# MCBSP register map
Vendor: Texas Instruments
Peripheral module from a debugger description file (folder 66AK2G0x_66AK2G1x).
Registers are 32-bit, read-write, reset values left out (the file's numbers can be read two ways) unless marked. A register's access mark holds for its fields unless they carry their own. Offsets are as the file gives them; lines under a group give offsets from that group; [hi:lo] are bit positions; {n}, {i} and the like mark numbered series; 'fields as' and 'values as' point back to an identical list; <NAME> marks a mode.

## MCBSP
0x00 MCBSP_DRR ro
  [31:0] DR — Data receive register value to be written to the data bus. Value is 0-FFFF FFFFh
0x04 MCBSP_DXR
  [31:0] DX — Data transmit register value to be loaded into the data transmit shift register (XSR).Value is 0-FFFF FFFFh.
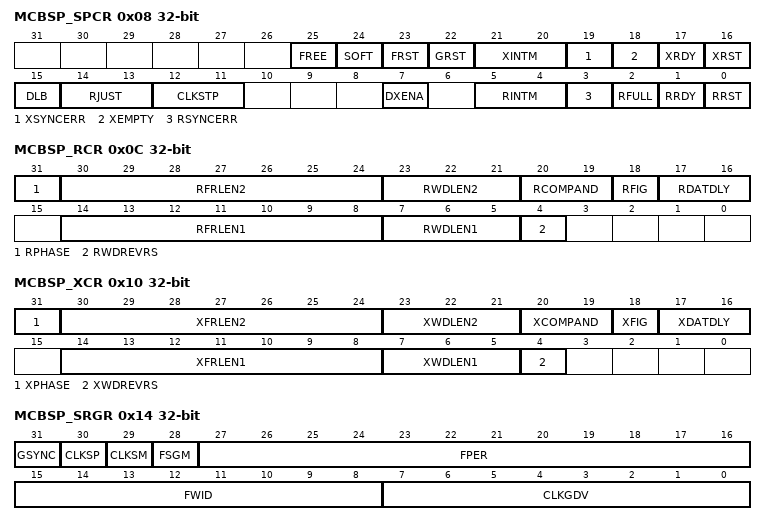
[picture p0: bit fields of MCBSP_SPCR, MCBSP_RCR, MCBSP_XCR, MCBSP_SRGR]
0x08 MCBSP_SPCR access per field
  [25] FREE rw — Free-running enable mode bit. This bit is used in conjunction with SOFT bit to determine state of serial port clock during emulation halt.
  [24] SOFT rw — Soft bit enable mode bit. This bit is used in conjunction with FREE bit to determine state of serial port clock during emulation halt. This bit has no effect if FREE = 1.
  [23] FRST rw — Frame-sync generator reset bit.
  [22] GRST rw — Sample-rate generator reset bit.
  [21:20] XINTM rw — Transmit interrupt (XINT) mode bit.
  [19] XSYNCERR rw — Transmit synchronization error bit. Writing a 1 to XSYNCERR sets the error condition when the transmitter is enabled (XRST = 1). Thus, it is used mainly for testing purposes or if this operation is desired.
  [18] XEMPTY ro — Transmit shift register empty bit.
  [17] XRDY ro — Transmitter ready bit.
  [16] XRST rw — Transmitter reset bit resets or enables the transmitter.
  [15] DLB rw — Digital loop back mode enable bit.
  [14:13] RJUST rw — Receive sign-extension and justification mode bit.
  [12:11] CLKSTP ro — Clock stop mode bit.
  [7] DXENA rw — DX enabler bit. See for details on the DX enabler bit.
  [5:4] RINTM rw — Receive interrupt (RINT) mode bit.
  [3] RSYNCERR rw — Receive synchronization error bit. Writing a 1 to RSYNCERR sets the error condition when the receiver is enabled (RRST = 1). Thus, it is used mainly for testing purposes or if this operation is desired.
  [2] RFULL ro — Receive shift register full bit.
  [1] RRDY ro — Receiver ready bit.
  [0] RRST rw — Receiver reset bit resets or enables the receiver.
0x0C MCBSP_RCR access per field
  [31] RPHASE rw — Receive phases bit.
  [30:24] RFRLEN2 rw — Specifies the receive frame length (number of words) in phase 2.
  [23:21] RWDLEN2 rw — Specifies the receive word length (number of bits) in phase 2.
  [20:19] RCOMPAND rw — Receive companding mode bit. Modes other than 00 are only enabled when RWDLEN1/2 bit is 000 (indicating 8-bit data).
  [18] RFIG rw — Receive frame ignore bit.
  [17:16] RDATDLY rw — Receive data delay bit.
  [14:8] RFRLEN1 rw — Specifies the receive frame length (number of words) in phase 1.
  [7:5] RWDLEN1 rw — Specifies the receive word length (number of bits) in phase 1.
  [4] RWDREVRS rw — Receive 32-bit reversal enable bit.
0x10 MCBSP_XCR access per field
  [31] XPHASE rw — Transmit phases bit.
  [30:24] XFRLEN2 rw — Specifies the transmit frame length (number of words) in phase 2.
  [23:21] XWDLEN2 rw — Specifies the transmit word length (number of bits) in phase 2.
  [20:19] XCOMPAND rw — Transmit companding mode bit. Modes other than 00 are only enabled when XWDLEN1/2 bit is 000 (indicating 8-bit data).
  [18] XFIG rw — Transmit frame ignore bit.
  [17:16] XDATDLY rw — Transmit data delay bit.
  [14:8] XFRLEN1 rw — Specifies the transmit frame length (number of words) in phase 1.
  [7:5] XWDLEN1 rw — Specifies the transmit word length (number of bits) in phase 1.
  [4] XWDREVRS rw — Transmit 32-bit reversal feature enable bit.
0x14 MCBSP_SRGR
  [31] GSYNC — Sample-rate generator clock synchronization bit is only used when CLKS drives the sample-rate generator clock (CLKSM = 0).
  [30] CLKSP — CLKS polarity clock edge select bit is only used when CLKS drives the sample-rate generator clock (CLKSM = 0).
  [29] CLKSM — Sample rate generator input clock mode bit. The sample rate generator can accept an input clock signal and divide it down according to CLKGDV to produce an output clock signal, CLKG. The frequency of CLKG is: CLKSM is used in conjunction with the SCLKME bit in the pin control register ( A DSP reset selects the McBSP internal input clock as the input clock and forces the CLKG frequency to 1/2 the McBSP internal input clock frequency.For more information about choosing an Input Clock for Sample Rate Generator with SCLKME bit see .
  [28] FSGM — Sample-rate generator transmit frame-synchronization mode bit is only used when FSXM = 1 inMCBSP_PCR.
  [27:16] FPER — 0-FFFh = Frame period value plus 1 specifies when the next frame-sync signal becomes active. Range is 1 to 4096 sample-rate generator clock (CLKG) periods.
  [15:8] FWID — 0-FFh = Frame width value plus 1 specifies the width of the frame-sync pulse (FSG) during its active period.
  [7:0] CLKGDV — 0-FFh = Sample-rate generator clock (CLKG) divider value is used as the divide-down number to generate the required sample-rate generator clock frequency.
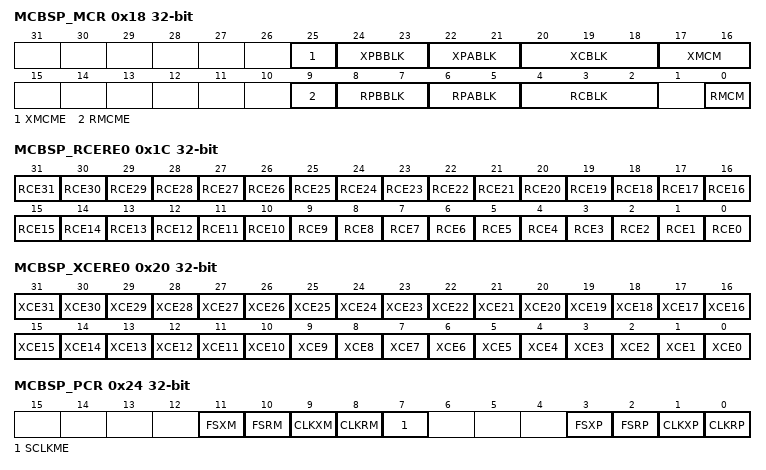
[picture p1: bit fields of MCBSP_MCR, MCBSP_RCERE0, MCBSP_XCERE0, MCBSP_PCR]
0x18 MCBSP_MCR access per field
  [25] XMCME rw — Transmit multichannel partition mode bit. XMCME is only applicable if channels can be individually disabled/enabled or masked/unmasked for transmission (XMCM is nonzero). XMCME determines whether only 32 channels or all 128 channels are to be individually selectable.0 = 2-partition mode. Only partitions A and B are used. You can control up to 32 channels in the transmit multichannel selection mode selected with the XMCM bit. 1 = 8-partition mode. All partitions (A through H) are used. You can control up to 128 channels in the transmit multichannel selection mode selected with the XMCM bit. You control the channels with the appropriate enhanced transmit channel enable register (XCEREn):
  [24:23] XPBBLK rw — Transmit partition B block bit.XPBBLK is only applicable if channels can be individually disabled/enabled and masked/unmasked (XMCM is nonzero) and the 2-partition mode is selected (XMCME = 0). Under these conditions, the McBSP transmitter can transmit or withhold data in any of the 32 channels that are assigned to partitions A and B of the transmitter. The 128 transmit channels of the McBSP are divided equally among 8 blocks (0 through 7). When XPBBLK is applicable, use the XPBBLK bit to assign one of the odd-numbered blocks (1, 3, 5, or 7) to partition B; use the XPABLK bit to assign one of the even-numbered blocks (0, 2, 4, or 6) to partition A. If you want to use more than 32 channels, you can change block assignments dynamically. You can assign a new block to one partition while the transmitter is handling activity in the other partition. For example, while the block in partition A is active, you can change which block is assigned to partition B. The XCBLK bit is regularly updated to indicate which block is active. When XMCM = 3h (for symmetric transmission and reception), the transmitter uses the receive block bits (RPABLK and RPBBLK) rather than the transmit block bits (XPABLK and XPBBLK).
  [22:21] XPABLK rw — Transmit partition A block bit.XPABLK is only applicable if channels can be individually disabled/enabled and masked/unmasked (XMCM is nonzero) and the 2-partition mode is selected (XMCME = 0). Under these conditions, the McBSP transmitter can transmit or withhold data in any of the 32 channels that are assigned to partitions A and B of the transmitter. See the XPBBLK bit description for more information about assigning blocks to partitions A and B.
  [20:18] XCBLK ro — Transmit current block indicator. XCBLK indicates which block of 16 channels is involved in the current McBSP transmission.
  [17:16] XMCM rw — Transmit multichannel selection mode bit. XMCM determines whether all channels or only selected channels are enabled and unmasked for transmission.
  [9] RMCME rw — Receive multichannel partition mode bit. RMCME is only applicable if channels can be individually disabled/enabled for reception (RMCM = 1). RMCME determines whether only 32 channels or all 128 channels are to be individually selectable.0 = 2-partition mode. Only partitions A and B are used. You can control up to 32 channels in the receive multichannel selection mode (RMCM = 1). Assign 16 channels to partition A with the RPABLK bit and assign 16 channels to partition B with the RPBBLK bit. You control the channels with the enhanced receive channel enable register partition A/B ( 1 = You can control up to 128 channels in the receive multichannel selection mode. You control the channels with the appropriate enhanced receive channel enable register (RCEREn):
  [8:7] RPBBLK rw — Receive partition B block bit.RPBBLK is only applicable if channels can be individually disabled/enabled (RMCM = 1) and the 2-partition mode is selected (RMCME = 0). Under these conditions, the McBSP receiver can accept or ignore data in any of the 32 channels that are assigned to partitions A and B of the receiver. The 128 receive channels of the McBSP are divided equally among 8 blocks (0 through 7). When RPBBLK is applicable, use the RPBBLK bit to assign one of the odd-numbered blocks (1, 3, 5, or 7) to partition B; use the RPABLK bit to assign one of the even-numbered blocks (0, 2, 4, or 6) to partition A. If you want to use more than 32 channels, you can change block assignments dynamically. You can assign a new block to one partition while the receiver is handling activity in the other partition. For example, while the block in partition A is active, you can change which block is assigned to partition B. The RCBLK bit is regularly updated to indicate which block is active. When XMCM = 3h (for symmetric transmission and reception), the transmitter uses the receive block bits (RPABLK and RPBBLK) rather than the transmit block bits (XPABLK and XPBBLK).
  [6:5] RPABLK rw — Receive partition A block bit.RPABLK is only applicable if channels can be individually disabled/enabled (RMCM = 1) and the 2-partition mode is selected (RMCME = 0). Under these conditions, the McBSP receiver can accept or ignore data in any of the 32 channels that are assigned to partitions A and B of the receiver. See the RPBBLK bit description for more information about assigning blocks to partitions A and B.
  [4:2] RCBLK ro — Receive current block indicator. RCBLK indicates which block of 16 channels is involved in the current McBSP reception.
  [0] RMCM rw — Receive multichannel selection mode bit. RMCM determines whether all channels or only selected channels are enabled for reception. The only channels enabled are those selected in the appropriate enhanced receive channel enable register (RCERE
0x1C MCBSP_RCERE0
  [n] RCE{n} (n=0..31) — Receive channel enable bit. For receive multichannel selection mode (RMCM = 1 inMCBSP_MCR).
0x20 MCBSP_XCERE0
  [n] XCE{n} (n=0..31) — Transmit channel enable bit. The role of this bit depends on which transmit multichannel mode is selected with the XMCM bit inMCBSP_MCR
0x24 MCBSP_PCR access per field
  [11] FSXM rw — Transmit frame-synchronization mode bit.
  [10] FSRM rw — Receive frame-synchronization mode bit.
  [9] CLKXM rw — Transmit clock mode bit. When CLKSTP bit inMCBSP_SPCR is cleared to 0:
  [8] CLKRM rw — Receive clock mode bit.
  [7] SCLKME rw — Sample rate generator input clock mode bit. The sample rate generator can produce a clock signal, CLKG. The frequency of CLKG is: SCLKME is used in conjunction with the CLKSM bit in the sample rate generator register ( A DSP reset selects the McBSP internal input clock as the input clock and forces the CLKG frequency to 1/2 the McBSP internal input clock frequency. 0 = The input clock for the sample rate generator is taken from the CLKS or from the McBSP internal input clock, depending on the value of the CLKSM bit in 1 = The input clock for the sample rate generator is taken from the CLKR pin or from the CLKX pin, depending on the value of the CLKSM bit in For more information about choosing an Input Clock for Sample Rate Generator with CLKSM bit see
  [3] FSXP rw — Transmit frame-synchronization polarity bit.
  [2] FSRP rw — Receive frame-synchronization polarity bit.
  [1] CLKXP rw — Transmit clock polarity bit.
  [0] CLKRP rw — Receive clock polarity bit.
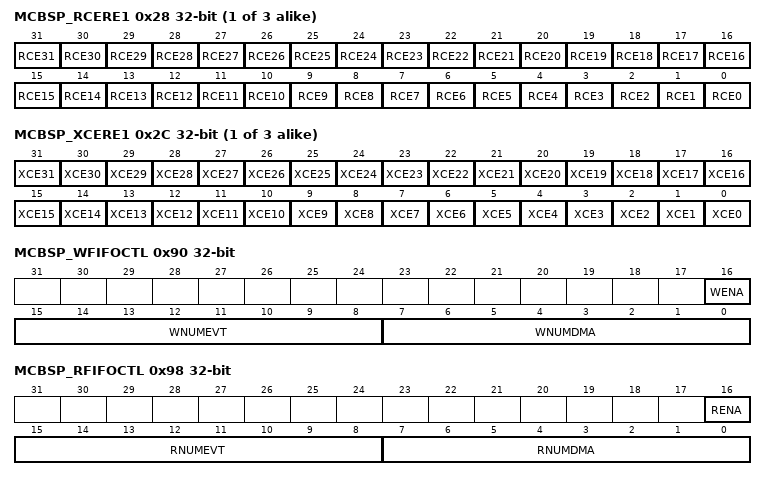
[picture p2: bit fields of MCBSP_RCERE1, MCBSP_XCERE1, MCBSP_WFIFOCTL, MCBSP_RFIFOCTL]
{0x20+8i} MCBSP_RCERE{i} (i=1..3)
  fields as MCBSP_RCERE0
{0x24+8i} MCBSP_XCERE{i} (i=1..3)
  fields as MCBSP_XCERE0
0x80 MCBSP_BFIFOREV ro
  [31:0] REV — TI internal data. Identifies revision of Buffer FIFO.
0x90 MCBSP_WFIFOCTL access per field
  [16] WENA rw — Write FIFO enable bit.
  [15:8] WNUMEVT rw — Write word count per DMA event (32-bit). When the Write FIFO has space for at leastWNUMEVT words of data, then an XEVT (transmit DMA event) is generated to the host/DMA controller. This value must be set prior to enabling the Write FIFO.
  [7:0] WNUMDMA rw — Write word count per transfer (32-bit words). Upon a transmit DMA event from the McBSP, WNUMDMA words are transferred from the Write FIFO to the McBSP. This value must be set prior to enabling the Write FIFO.
0x94 MCBSP_WFIFOSTS ro
  [7:0] WLVL — Write level. Number of 32-bit words currently in the Write FIFO.
0x98 MCBSP_RFIFOCTL access per field
  [16] RENA rw — Read FIFO enable bit.
  [15:8] RNUMEVT rw — Read word count per DMA event (32-bit). When the Read FIFO contains at leastRNUMEVT words of data, then an REVT (receive DMA event) is generated to the host/DMA controller. This value must be set prior to enabling the Read FIFO.
  [7:0] RNUMDMA rw — Read word count per transfer (32-bit words). Upon a receive DMA event from the McBSP, the Read FIFO readsRNUMDMA words from the McBSP. This value must be set prior to enabling the Read FIFO.
0x9C MCBSP_RFIFOSTS ro
  [7:0] RLVL — Read level. Number of 32-bit words currently in the Read FIFO.
